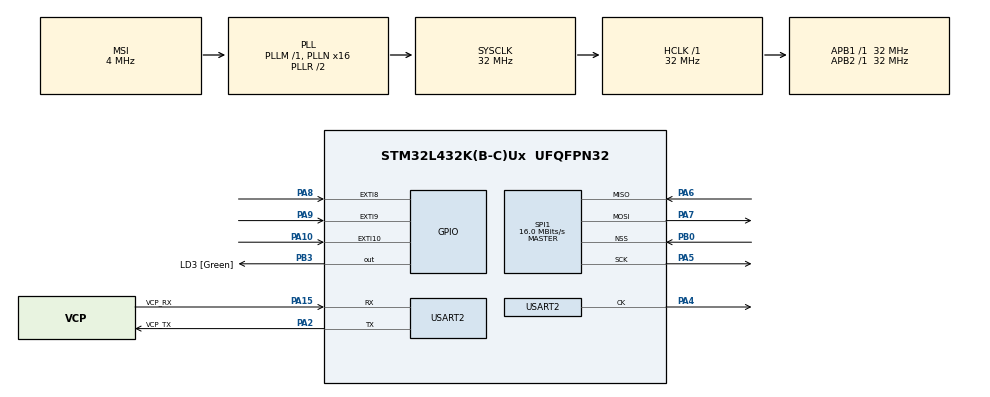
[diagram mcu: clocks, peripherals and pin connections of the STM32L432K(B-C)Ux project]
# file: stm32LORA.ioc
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Mcu.Family=STM32L4
Mcu.Name=STM32L432K(B-C)Ux
Mcu.Package=UFQFPN32
NVIC.PriorityGroup=NVIC_PRIORITYGROUP_4
NVIC.SPI1_IRQn=true\:0\:0\:false\:false\:true\:true\:true\:true
NVIC.USART2_IRQn=true\:0\:0\:false\:false\:true\:true\:true\:true
PA0.GPIO_Label=MCO [High speed clock in]
PA0.Mode=HSE-External-Clock-Source-for-LittleOrca
PA0.Signal=RCC_CK_IN
PA10.Signal=GPXTI10
PA13\ (JTMS-SWDIO).GPIO_Label=SWDIO
PA13\ (JTMS-SWDIO).Mode=Serial_Wire
PA13\ (JTMS-SWDIO).Signal=SYS_JTMS-SWDIO
PA14\ (JTCK-SWCLK).GPIO_Label=SWCLK
PA14\ (JTCK-SWCLK).Mode=Serial_Wire
PA14\ (JTCK-SWCLK).Signal=SYS_JTCK-SWCLK
PA15\ (JTDI).GPIO_Label=VCP_RX
PA15\ (JTDI).Mode=Synchronous
PA15\ (JTDI).Signal=USART2_RX
PA2.GPIO_Label=VCP_TX
PA2.Mode=Synchronous
PA2.Signal=USART2_TX
PA4.Mode=Synchronous
PA4.Signal=USART2_CK
PA5.Mode=Full_Duplex_Master
PA5.Signal=SPI1_SCK
PA6.Mode=Full_Duplex_Master
PA6.Signal=SPI1_MISO
PA7.Mode=Full_Duplex_Master
PA7.Signal=SPI1_MOSI
PA8.Signal=GPXTI8
PA9.Signal=GPXTI9
PB0.Mode=NSS_Signal_Hard_Input
PB0.Signal=SPI1_NSS
PB3\ (JTDO-TRACESWO).GPIO_Label=LD3 [Green]
PB3\ (JTDO-TRACESWO).Signal=GPIO_Output
PC14-OSC32_IN\ (PC14).Mode=LSE-External-Oscillator
PC14-OSC32_IN\ (PC14).Signal=RCC_OSC32_IN
PC15-OSC32_OUT\ (PC15).Mode=LSE-External-Oscillator
PC15-OSC32_OUT\ (PC15).Signal=RCC_OSC32_OUT
ProjectManager.HeapSize=0x200
ProjectManager.StackSize=0x400
ProjectManager.TargetToolchain=STM32CubeIDE
RCC.AHBFreq_Value=32000000
RCC.APB1Freq_Value=32000000
RCC.APB1TimFreq_Value=32000000
RCC.APB2Freq_Value=32000000
RCC.APB2TimFreq_Value=32000000
RCC.CortexFreq_Value=32000000
RCC.HCLKFreq_Value=32000000
RCC.HSE_VALUE=8000000
RCC.HSI16_VALUE=16000000
RCC.HSI48_VALUE=48000000
RCC.HSI_VALUE=16000000
RCC.MSI_VALUE=4000000
RCC.PLLMUL=RCC_PLLMUL_4
RCC.PLLN=16
RCC.SYSCLKFreq_VALUE=32000000
RCC.SYSCLKSource=RCC_SYSCLKSOURCE_PLLCLK
RCC.VCOOutputFreq_Value=64000000
SPI1.CalculateBaudRate=16.0 MBits/s
SPI1.Direction=SPI_DIRECTION_2LINES
SPI1.Mode=SPI_MODE_MASTER
SPI1.VirtualNSS=VM_NSSHARD
SPI1.VirtualType=VM_MASTER
USART2.VirtualMode-Synchronous=VM_SYNC
board=NUCLEO-L432KC

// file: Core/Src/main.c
/* USER CODE BEGIN Header */
/**
  ******************************************************************************
  * @file           : main.c
  * @brief          : Main program body
  ******************************************************************************
  * @attention
  *
  * Copyright (c) 2024 STMicroelectronics.
  * All rights reserved.
  *
  * This software is licensed under terms that can be found in the LICENSE file
  * in the root directory of this software component.
  * If no LICENSE file comes with this software, it is provided AS-IS.
  *
  ******************************************************************************
  */
/* USER CODE END Header */
#include "main.h"
#include <string.h>
#include <stdio.h>
#include <stdlib.h>

// RFM95 register addresses
#define REG_FIFO            0x00
#define REG_OP_MODE         0x01
#define REG_FRF_MSB         0x06
#define REG_FRF_MID         0x07
#define REG_FRF_LSB         0x08
#define REG_PA_CONFIG       0x09
#define REG_LORA_CONFIG_1   0x1D
#define REG_FIFO_ADDR_PTR   0x0D
#define REG_FIFO_TX_BASE    0x0E
#define REG_FIFO_RX_BASE    0x0F
#define REG_FIFO_RX_CURRENT_ADDR 0x10
#define REG_IRQ_FLAGS       0x12
#define REG_DIO_MAPPING_1   0x40
#define REG_MODEM_CONFIG_1  0x1D

SPI_HandleTypeDef hspi1;

USART_HandleTypeDef husart2;

void SystemClock_Config(void);
static void MX_GPIO_Init(void);
static void MX_USART2_Init(void);
static void MX_SPI1_Init(void);

int main(void)
{
  /* USER CODE BEGIN 1 */
  LoRa_Init();

  /* USER CODE END 1 */

  /* MCU Configuration--------------------------------------------------------*/

  /* Reset of all peripherals, Initializes the Flash interface and the Systick. */
  HAL_Init();

  /* Configure the system clock */
  SystemClock_Config();

  /* Initialize all configured peripherals */
  MX_GPIO_Init();
  MX_USART2_Init();
  MX_SPI1_Init();

  /* Infinite loop */
  while (1)
  {

	    // Your data to be transmitted
	    uint8_t dataToSend[] = "Hello, LoRa!";

	    // Send data to LoRa module
	    LoRa_SendData(dataToSend, sizeof(dataToSend));

	    // Delay before sending again (you may need to adjust this based on your requirements)
	    HAL_Delay(5000);

  }
}

void LoRa_Init() {
  // Implement the initialization of the LoRa module here
  // This may include setting LoRa parameters, frequency, etc.

	  // Set LoRa mode, sleep mode
	  HAL_GPIO_WritePin(GPIOB, GPIO_PIN_0, GPIO_PIN_RESET);  // Set NSS low
	  HAL_SPI_Transmit(&hspi1, REG_OP_MODE | 0x80, 1, HAL_MAX_DELAY);  // Set write command
	  HAL_SPI_Transmit(&hspi1, 0x80, 1, HAL_MAX_DELAY);  // Set sleep mode
	  HAL_GPIO_WritePin(GPIOB, GPIO_PIN_0, GPIO_PIN_SET);  // Set NSS high

	  // Set LoRa mode, standby mode
	  HAL_GPIO_WritePin(GPIOB, GPIO_PIN_0, GPIO_PIN_RESET);  // Set NSS low
	  HAL_SPI_Transmit(&hspi1, REG_OP_MODE | 0x80, 1, HAL_MAX_DELAY);  // Set write command
	  HAL_SPI_Transmit(&hspi1, 0x81, 1, HAL_MAX_DELAY);  // Set standby mode
	  HAL_GPIO_WritePin(GPIOB, GPIO_PIN_0, GPIO_PIN_SET);  // Set NSS high

	  // Configure frequency (915MHz in this example)
	  uint32_t frequency = 915000000;  // Set your desired frequency
	  uint32_t frf = (frequency << 19) / 32000000;

	  HAL_GPIO_WritePin(GPIOB, GPIO_PIN_0, GPIO_PIN_RESET);  // Set NSS low
	  HAL_SPI_Transmit(&hspi1, REG_FRF_MSB | 0x80, 1, HAL_MAX_DELAY);  // Set write command
	  HAL_SPI_Transmit(&hspi1, (frf >> 16) & 0xFF, 1, HAL_MAX_DELAY);
	  HAL_SPI_Transmit(&hspi1, (frf >> 8) & 0xFF, 1, HAL_MAX_DELAY);
	  HAL_SPI_Transmit(&hspi1, frf & 0xFF, 1, HAL_MAX_DELAY);
	  HAL_GPIO_WritePin(GPIOB, GPIO_PIN_0, GPIO_PIN_SET);  // Set NSS high

	  // Configure LoRa parameters
	  HAL_GPIO_WritePin(GPIOB, GPIO_PIN_0, GPIO_PIN_RESET);  // Set NSS low
	  HAL_SPI_Transmit(&hspi1, REG_LORA_CONFIG_1 | 0x80, 1, HAL_MAX_DELAY);  // Set write command
	  HAL_SPI_Transmit(&hspi1, 0x72, 1, HAL_MAX_DELAY);  // SF = 7, BW = 125kHz
	  HAL_GPIO_WritePin(GPIOB, GPIO_PIN_0, GPIO_PIN_SET);  // Set NSS high

	  // Set PA config
	  HAL_GPIO_WritePin(GPIOB, GPIO_PIN_0, GPIO_PIN_RESET);  // Set NSS low
	  HAL_SPI_Transmit(&hspi1, REG_PA_CONFIG | 0x80, 1, HAL_MAX_DELAY);  // Set write command
	  HAL_SPI_Transmit(&hspi1, 0x8F, 1, HAL_MAX_DELAY);  // Set PA max power
	  HAL_GPIO_WritePin(GPIOB, GPIO_PIN_0, GPIO_PIN_SET);  // Set NSS high

}

void LoRa_SendData(uint8_t *data, uint16_t size) {
  // Implement code to send data to LoRa module through SPI
  // You'll need to handle the SPI communication based on your specific setup
  // Use the HAL_SPI_Transmit function or similar for SPI communication

	  // Set LoRa mode, standby mode
	  HAL_GPIO_WritePin(GPIOB, GPIO_PIN_0, GPIO_PIN_RESET);  // Set NSS low
	  HAL_SPI_Transmit(&hspi1, REG_OP_MODE | 0x80, 1, HAL_MAX_DELAY);  // Set write command
	  HAL_SPI_Transmit(&hspi1, 0x81, 1, HAL_MAX_DELAY);  // Set standby mode
	  HAL_GPIO_WritePin(GPIOB, GPIO_PIN_0, GPIO_PIN_SET);  // Set NSS high

	  // Set FIFO address pointer
	  HAL_GPIO_WritePin(GPIOB, GPIO_PIN_0, GPIO_PIN_RESET);  // Set NSS low
	  HAL_SPI_Transmit(&hspi1, REG_FIFO_ADDR_PTR | 0x80, 1, HAL_MAX_DELAY);  // Set write command
	  HAL_SPI_Transmit(&hspi1, 0x80, 1, HAL_MAX_DELAY);  // Set FIFO address pointer to 0
	  HAL_GPIO_WritePin(GPIOB, GPIO_PIN_0, GPIO_PIN_SET);  // Set NSS high

	  // Write data to FIFO
	  HAL_GPIO_WritePin(GPIOB, GPIO_PIN_0, GPIO_PIN_RESET);  // Set NSS low
	  HAL_SPI_Transmit(&hspi1, REG_FIFO | 0x80, 1, HAL_MAX_DELAY);  // Set write command

	  for (uint16_t i = 0; i < size; i++) {
	    HAL_SPI_Transmit(&hspi1, data[i], 1, HAL_MAX_DELAY);

	    // Print the current byte to USART2
	    char hex[3];
	    snprintf(hex, sizeof(hex), "%02X", data[i]);
	    USART2_SendString(hex);
	    USART2_SendString(" ");
	  }

	  HAL_GPIO_WritePin(GPIOB, GPIO_PIN_0, GPIO_PIN_SET);  // Set NSS high

	  // Set LoRa mode, transmit mode
	  HAL_GPIO_WritePin(GPIOB, GPIO_PIN_0, GPIO_PIN_RESET);  // Set NSS low
	  HAL_SPI_Transmit(&hspi1, REG_OP_MODE | 0x80, 1, HAL_MAX_DELAY);  // Set write command
	  HAL_SPI_Transmit(&hspi1, 0x83, 1, HAL_MAX_DELAY);  // Set transmit mode
	  HAL_GPIO_WritePin(GPIOB, GPIO_PIN_0, GPIO_PIN_SET);  // Set NSS high

	  /*
	  USART2_SendString("Sending data to LoRa: ");
	  USART2_SendString((char *)data);
	  USART2_SendString("\r\n");
	*/
}

void USART2_SendString(char *str) {
  HAL_USART_Transmit(&husart2, (uint8_t *)str, strlen(str), HAL_MAX_DELAY);
}

void SystemClock_Config(void)
{
  RCC_OscInitTypeDef RCC_OscInitStruct = {0};
  RCC_ClkInitTypeDef RCC_ClkInitStruct = {0};

  /** Configure the main internal regulator output voltage
  */
  if (HAL_PWREx_ControlVoltageScaling(PWR_REGULATOR_VOLTAGE_SCALE1) != HAL_OK)
  {
    Error_Handler();
  }

  /** Configure LSE Drive Capability
  */
  HAL_PWR_EnableBkUpAccess();
  __HAL_RCC_LSEDRIVE_CONFIG(RCC_LSEDRIVE_LOW);

  /** Initializes the RCC Oscillators according to the specified parameters
  * in the RCC_OscInitTypeDef structure.
  */
  RCC_OscInitStruct.OscillatorType = RCC_OSCILLATORTYPE_LSE|RCC_OSCILLATORTYPE_MSI;
  RCC_OscInitStruct.LSEState = RCC_LSE_ON;
  RCC_OscInitStruct.MSIState = RCC_MSI_ON;
  RCC_OscInitStruct.MSICalibrationValue = 0;
  RCC_OscInitStruct.MSIClockRange = RCC_MSIRANGE_6;
  RCC_OscInitStruct.PLL.PLLState = RCC_PLL_ON;
  RCC_OscInitStruct.PLL.PLLSource = RCC_PLLSOURCE_MSI;
  RCC_OscInitStruct.PLL.PLLM = 1;
  RCC_OscInitStruct.PLL.PLLN = 16;
  RCC_OscInitStruct.PLL.PLLP = RCC_PLLP_DIV7;
  RCC_OscInitStruct.PLL.PLLQ = RCC_PLLQ_DIV2;
  RCC_OscInitStruct.PLL.PLLR = RCC_PLLR_DIV2;
  if (HAL_RCC_OscConfig(&RCC_OscInitStruct) != HAL_OK)
  {
    Error_Handler();
  }

  /** Initializes the CPU, AHB and APB buses clocks
  */
  RCC_ClkInitStruct.ClockType = RCC_CLOCKTYPE_HCLK|RCC_CLOCKTYPE_SYSCLK
                              |RCC_CLOCKTYPE_PCLK1|RCC_CLOCKTYPE_PCLK2;
  RCC_ClkInitStruct.SYSCLKSource = RCC_SYSCLKSOURCE_PLLCLK;
  RCC_ClkInitStruct.AHBCLKDivider = RCC_SYSCLK_DIV1;
  RCC_ClkInitStruct.APB1CLKDivider = RCC_HCLK_DIV1;
  RCC_ClkInitStruct.APB2CLKDivider = RCC_HCLK_DIV1;

  if (HAL_RCC_ClockConfig(&RCC_ClkInitStruct, FLASH_LATENCY_1) != HAL_OK)
  {
    Error_Handler();
  }

  /** Enable MSI Auto calibration
  */
  HAL_RCCEx_EnableMSIPLLMode();
}

static void MX_SPI1_Init(void)
{

  /* SPI1 parameter configuration*/
  hspi1.Instance = SPI1;
  hspi1.Init.Mode = SPI_MODE_MASTER;
  hspi1.Init.Direction = SPI_DIRECTION_2LINES;
  hspi1.Init.DataSize = SPI_DATASIZE_4BIT;
  hspi1.Init.CLKPolarity = SPI_POLARITY_LOW;
  hspi1.Init.CLKPhase = SPI_PHASE_1EDGE;
  hspi1.Init.NSS = SPI_NSS_HARD_INPUT;
  hspi1.Init.BaudRatePrescaler = SPI_BAUDRATEPRESCALER_2;
  hspi1.Init.FirstBit = SPI_FIRSTBIT_MSB;
  hspi1.Init.TIMode = SPI_TIMODE_DISABLE;
  hspi1.Init.CRCCalculation = SPI_CRCCALCULATION_DISABLE;
  hspi1.Init.CRCPolynomial = 7;
  hspi1.Init.CRCLength = SPI_CRC_LENGTH_DATASIZE;
  hspi1.Init.NSSPMode = SPI_NSS_PULSE_ENABLE;
  if (HAL_SPI_Init(&hspi1) != HAL_OK)
  {
    Error_Handler();
  }

}

static void MX_USART2_Init(void)
{

  husart2.Instance = USART2;
  husart2.Init.BaudRate = 115200;
  husart2.Init.WordLength = USART_WORDLENGTH_8B;
  husart2.Init.StopBits = USART_STOPBITS_1;
  husart2.Init.Parity = USART_PARITY_NONE;
  husart2.Init.Mode = USART_MODE_TX_RX;
  husart2.Init.CLKPolarity = USART_POLARITY_LOW;
  husart2.Init.CLKPhase = USART_PHASE_1EDGE;
  husart2.Init.CLKLastBit = USART_LASTBIT_DISABLE;
  if (HAL_USART_Init(&husart2) != HAL_OK)
  {
    Error_Handler();
  }

}

static void MX_GPIO_Init(void)
{
  GPIO_InitTypeDef GPIO_InitStruct = {0};

  /* GPIO Ports Clock Enable */
  __HAL_RCC_GPIOC_CLK_ENABLE();
  __HAL_RCC_GPIOA_CLK_ENABLE();
  __HAL_RCC_GPIOB_CLK_ENABLE();

  /*Configure GPIO pin Output Level */
  HAL_GPIO_WritePin(LD3_GPIO_Port, LD3_Pin, GPIO_PIN_RESET);

  /*Configure GPIO pins : PA8 PA9 PA10 */
  GPIO_InitStruct.Pin = GPIO_PIN_8|GPIO_PIN_9|GPIO_PIN_10;
  GPIO_InitStruct.Mode = GPIO_MODE_IT_RISING;
  GPIO_InitStruct.Pull = GPIO_NOPULL;
  HAL_GPIO_Init(GPIOA, &GPIO_InitStruct);

  /*Configure GPIO pin : LD3_Pin */
  GPIO_InitStruct.Pin = LD3_Pin;
  GPIO_InitStruct.Mode = GPIO_MODE_OUTPUT_PP;
  GPIO_InitStruct.Pull = GPIO_NOPULL;
  GPIO_InitStruct.Speed = GPIO_SPEED_FREQ_LOW;
  HAL_GPIO_Init(LD3_GPIO_Port, &GPIO_InitStruct);

}

void Error_Handler(void)
{
  __disable_irq();
  while (1)
  {
  }
}
